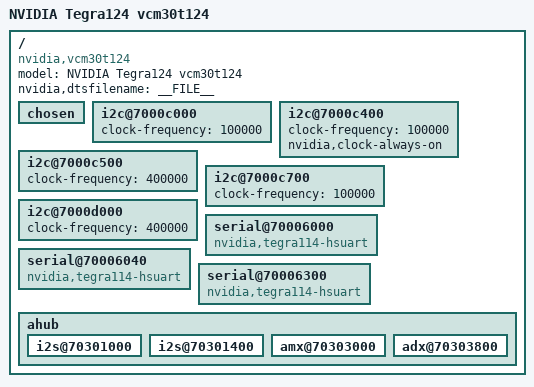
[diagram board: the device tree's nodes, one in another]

 /dts-v1/;

#include "tegra124.dtsi"

/ {
	model = "NVIDIA Tegra124 vcm30t124";
	compatible = "nvidia,vcm30t124", "nvidia,tegra124";
	nvidia,dtsfilename = __FILE__;
	#address-cells = <1>;
	#size-cells = <1>;

	chosen {
	};

	i2c@7000c000 {
		status = "okay";
		clock-frequency = <100000>;
	};

	i2c@7000c400 {
		status = "okay";
		clock-frequency = <100000>;
		nvidia,clock-always-on;
	};

	i2c@7000c500 {
		status = "okay";
		clock-frequency = <400000>;
	};

	i2c@7000c700 {
		status = "okay";
		clock-frequency = <100000>;
	};

	i2c@7000d000 {
		status = "okay";
		clock-frequency = <400000>;
	};

        serial@70006000 {
                compatible = "nvidia,tegra114-hsuart";
                status = "okay";
        };

        serial@70006040 {
                compatible = "nvidia,tegra114-hsuart";
                status = "okay";
        };

        serial@70006300 {
                compatible = "nvidia,tegra114-hsuart";
                status = "okay";
        };

	ahub {
		status = "okay";

		i2s@70301000 {
			status = "okay";
		};
		i2s@70301400 {
			status = "okay";
		};
		amx@70303000 {
			status = "okay";
		};
		adx@70303800 {
			status = "okay";
		};
	};
};
